# NANO100BN_v1 register map
File version: 1.0
Registers are 32-bit, read-write, reset 0x0 unless marked. A register's access mark holds for its fields unless they carry their own. Offsets are from the block's base; [hi:lo] are bit positions; {n}, {i} and the like mark numbered series; 'fields as' and 'values as' point back to an identical list.

## ADC — ADC Register Map
Base 0x400E0000
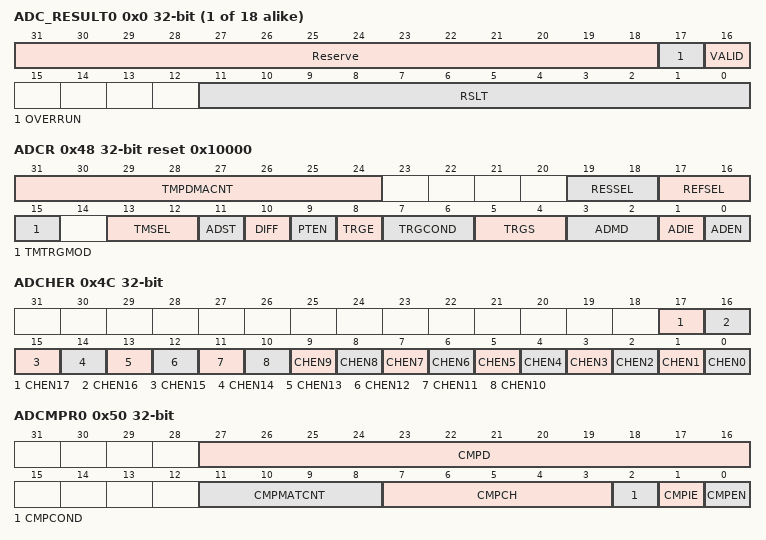
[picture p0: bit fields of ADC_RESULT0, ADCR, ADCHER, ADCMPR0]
{0x0+4i} ADC_RESULT{i} ro (i=0..17) — A/D Data Register {i}
  [31:18] Reserve — Reserved
  [17] OVERRUN — Over Run Flag. It is a mirror to OVERRUN bit in ADC_RESULTx
  [16] VALID — Data Valid Flag. It is a mirror of VALID bit in ADC_RESULTx
  [11:0] RSLT — A/D Conversion Result. This field contains 12 bits conversion results.
0x48 ADCR reset 0x10000 — A/D Control Register
  [31:24] TMPDMACNT — PDMA Count. When each timer event occur PDMA will transfer TMPDMACNT +1 ADC result in the amount of this register setting. Note: The total amount of PDMA transferring data should be set in PDMA byte count register. When PDMA finish is set, ADC will not be enabled and start transfer even though the timer event occurred
  [19:18] RESSEL — Resolution Selection
  [17:16] REFSEL — Reference Voltage Source Selection
  [15] TMTRGMOD — Timer Event Trigger ADC Conversion
    0=This function Disabled; 1=ADC Enabled by TIMER OUT event
  [13:12] TMSEL — Select A/D Enable Time-out Source
  [11] ADST — A/D Conversion Start. ADST bit can be set to 1 from two sources: software write and external pin STADC. ADST is cleared to 0 by hardware automatically at the end of single mode and single-cycle scan mode on specified channels. In continuous scan mode, A/D conversion is continuously performed sequentially unless software writes 0 to this bit or chip reset. Note: After ADC conversion done, SW needs to wait at least one ADC clock before to set this bit high again.
    0=Conversion stopped and A/D converter enter idle state; 1=Conversion starts
  [10] DIFF — Differential Mode Selection. 1:ADC is operated in differential mode. 0:ADC is operated in single-ended mode. Note: Calibration should calibrated each time when switching between single-ended and differential mode
  [9] PTEN — PDMA Transfer Enable
    0=PDMA data transfer Disabled; 1=PDMA data transfer in ADC_RESULT 0~17 Enabled
  [8] TRGE — External Trigger Enable. Enable or disable triggering of A/D conversion by external STADC pin.
    0=Disabled,; 1=Enabled,
  [7:6] TRGCOND — External Trigger Condition
  [5:4] TRGS — Hardware Trigger Source
  [3:2] ADMD — A/D Converter Operation Mode
  [1] ADIE — A/D Interrupt Enable. A/D conversion end interrupt request is generated if ADIE bit is set to 1.
    0=A/D interrupt function Disabled; 1=A/D interrupt function Enabled
  [0] ADEN — A/D Converter Enable. Before starting A/D conversion, this bit should be set to 1. Clear it to 0 to disable A/D converter analog circuit power consumption.
    0=Disabled; 1=Enabled
0x4C ADCHER — A/D Channel Enable Register
  [all] fields
    0=Disabled; 1=Enabled
  [17] CHEN17 — Analog Input Channel 17 Enable (Convert AVSS)
  [16] CHEN16 — Analog Input Channel 16 Enable (Convert AVDD)
  [15] CHEN15 — Analog Input Channel 15 Enable (Convert Int_VREF)
  [14] CHEN14 — Analog Input Channel 14 Enable (Convert VTEMP)
  [13] CHEN13 — Analog Input Channel 13 Enable (Convert DAC1 Output Voltage)
  [12] CHEN12 — Analog Input Channel 12 Enable (Convert DAC0 Output Voltage)
  [11] CHEN11 — Analog Input Channel 11 Enable(Convert input voltage from PD.3 )
  [10] CHEN10 — Analog Input Channel 10 Enable (Convert Input Voltage from PD.2 )
  [9] CHEN9 — Analog Input Channel 9 Enable for DAC1 (Convert Input Voltage from PD.1 )
  [8] CHEN8 — Analog Input Channel 8 Enable for DAC0 (Convert Input Voltage from PD.0 )
  [7] CHEN7 — Analog Input Channel 7 Enable (Convert Input Voltage from PA.7 )
  [6] CHEN6 — Anaslog Input Channel 6 Enable (Convert Input Voltage from PA.6 )
  [5] CHEN5 — Analog Input Channel 5 Enable (Convert Input Voltage from PA.5 )
  [4] CHEN4 — Analog Input Channel 4 Enable (Convert Input Voltage from PA.4 )
  [3] CHEN3 — Analog Input Channel 3 Enable(Convert input voltage from PA.3 )
  [2] CHEN2 — Analog Input Channel 2 Enable (Convert Input Voltage from PA.2 )
  [1] CHEN1 — Analog Input Channel 1 Enable(Convert input voltage from PA.1 )
  [0] CHEN0 — Analog Input Channel 0 Enable (Convert Input Voltage from PA.0 ). If more than one channel in single mode is enabled by software, the least channel is converted and other enabled channels will be ignored.
0x50 ADCMPR0 — A/D Compare Register 0
  [27:16] CMPD — Comparison Data. The 12 bits data is used to compare with conversion result of specified channel. Software can use it to monitor the external analog input pin voltage variation in scan mode without imposing a load on software.
  [11:8] CMPMATCNT — Compare Match Count. When the specified A/D channel analog conversion result matches the compare condition defined by CMPCOND[2], the internal match counter will increase 1. When the internal counter reaches the value to (CMPMATCNT +1), the CMPF bit will be set.
  [7:3] CMPCH — Compare Channel Selection
  [2] CMPCOND — Compare Condition. Note: When the internal counter reaches the value to (CMPMATCNT +1), the CMPF bit will be set.
    0=Set the compare condition as that when a 12-bit A/D conversion result is less than the 12-bit CMPD (ADCMPRx[27:16]), the internal match counter will increase one; 1=Set the compare condition as that when a 12-bit A/D conversion result is greater or equal to the 12-bit CMPD (ADCMPRx[27:16]), the internal match counter will increase by one
  [1] CMPIE — Compare Interrupt Enable. If the compare function is enabled and the compare condition matches the setting of CMPCOND and CMPMATCNT, CMPF bit will be asserted, in the meanwhile, if CMPIE is set to 1, a compare interrupt request is generated.
    0=Compare function interrupt Disabled; 1=Compare function interrupt Enabled
  [0] CMPEN — Compare Enable. Set this bit to 1 to enable compare CMPD[11:0] with specified channel conversion result when converted data is loaded into ADC_RESULTx register. When this bit is set to 1, and CMPMATCNT is 0, the CMPF will be set once the match is hit
    0=Compare Disabled; 1=Compare Enabled
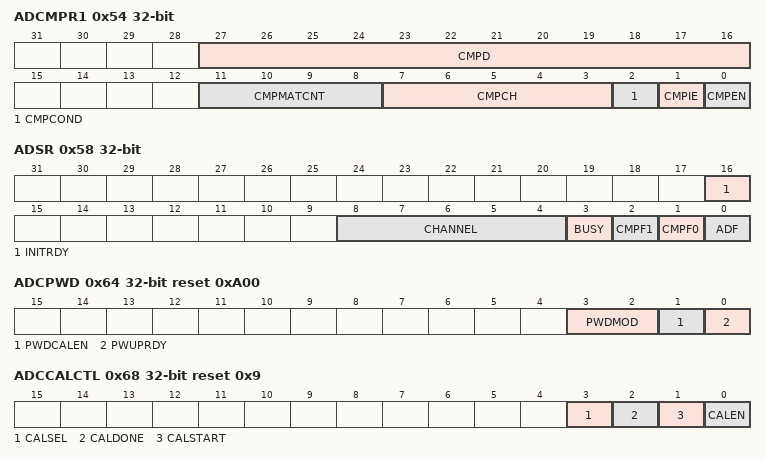
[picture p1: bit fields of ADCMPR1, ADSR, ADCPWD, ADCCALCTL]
0x54 ADCMPR1 — A/D Compare Register 1
  fields as ADCMPR0
0x58 ADSR — A/D Status Register
  [16] INITRDY — ADC Power-up Sequence Completed. Note: This bit will be set after system reset occurred and automatically cleared by power-up event.
    0=ADC has been powered up since he last system reset; 1=ADC not powered up after system reset
  [8:4] CHANNEL — Current Conversion Channel. It is read only.
  [3] BUSY — BUSY/IDLE. It is read only.
    0=A/D converter is in idle state; 1=A/D converter is busy at conversion
  [2] CMPF1 — Compare Flag. When the selected channel A/D conversion result meets setting condition in ADCMPR1 then this bit is set to 1. And it is cleared by writing 1 to self. This flag can be cleared by writing 1 to it. Note: when this flag is set, the matching counter will be reset to 0,and continue to count when user write 1 to clear CMPF1
    0=Conversion result in ADC_RESULTx does not meet ADCMPR1 setting; 1=Conversion result in ADC_RESULTx meets ADCMPR1 setting
  [1] CMPF0 — Compare Flag. When the selected channel A/D conversion result meets setting condition in ADCMPR0 then this bit is set to 1. And it is cleared by writing 1 to self. This flag can be cleared by writing 1 to it. Note: When this flag is set, the matching counter will be reset to 0,and continue to count when user write 1 to clear CMPF0
    0=Conversion result in ADC_RESULTx does not meet ADCMPR0setting; 1=Conversion result in ADC_RESULTx meets ADCMPR0setting
  [0] ADF — A/D Conversion End Flag. A status flag that indicates the end of A/D conversion. ADF is set to 1 at these two conditions: When A/D conversion ends in single mode. When A/D conversion ends on all specified channels in scan mode. This flag can be cleared by writing 1 to it.
0x60 ADPDMA ro — A/D PDMA current transfer data Register
  [11:0] AD_PDMA — ADC PDMA Current Transfer Data Register. When PDMA transferring, read this register can monitor current PDMA transfer data. This is a read only register.
0x64 ADCPWD reset 0xA00 — ADC Power Management Register
  [3:2] PWDMOD — Power-down Mode
  [1] PWDCALEN — Power up Calibration Function Enable
    0=Power up without calibration; 1=Power up with calibration
  [0] PWUPRDY — ADC Power-up Sequence Completed and Ready for Conversion
    0=ADC is not ready for conversion;may be in power down state or in the progress of power up; 1=ADC is ready for conversion
0x68 ADCCALCTL reset 0x9 — ADC Calibration Control Register
  [3] CALSEL — Select Calibration Functional Block
    0=Load calibration functional block; 1=Calibration functional block
  [2] CALDONE — Calibrate Functional Block Complete
    0=Not yet; 1=Selected functional block complete
  [1] CALSTART — Calibration Functional Blcok Start
    0=Stops calibration functional block; 1=Starts calibration functional block
  [0] CALEN — Calibraion Function Enable. Enable this bit to turn on the calibration function block.
    0=(BYPASSCAL); 1=Enabled
0x6C ADCCALWORD reset not defined — A/D calibration load word register
  [6:0] CALWORD — Calibration Word Register. Write to this register with the previous calibration word before load calibration action. Read this register after calibration done. Note: The calibration block contains two parts "CALIBRATION" and "LOAD CALIBRATION"; if thecalibration block is config as "CALIBRATION"; then this register represent the result of calibration when calibration is completed; if config as "LOAD CALIBRATION" ; config this register before loading calibration action, after loading calibration complete, the laoded calibration word will apply to the ADC;while in loading calibration function the loaded value will not be equal to the orginal CALWORD until calibration is done.
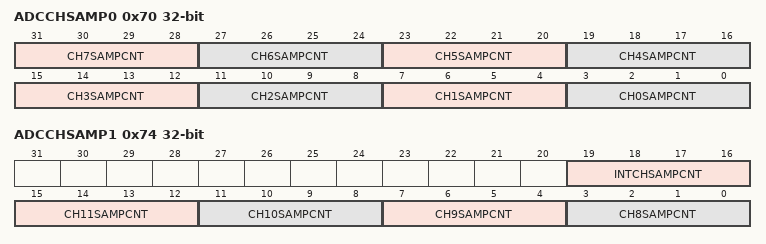
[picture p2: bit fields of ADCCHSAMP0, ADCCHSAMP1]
0x70 ADCCHSAMP0 — ADC Channel Sampling Time Counter Register Group 0
  [4n+3:4n] CH{n}SAMPCNT (n=1..7) — Channel {n} Sampling Counter. The same as Channel 0 sampling counter table.
  [3:0] CH0SAMPCNT — Channel 0 Sampling Counter
0x74 ADCCHSAMP1 — ADC Channel Sampling Time Counter Register Group 1
  [19:16] INTCHSAMPCNT — Internal Channel (VTEMP, AVDD, AVSS, Int_VREF, DAC0, DAC1) Sampling Counter. The same as Channel 0 sampling counter table.
  [4n-29:4n-32] CH{n}SAMPCNT (n=8..11) — Channel {n} Sampling Counter. The same as Channel 0 sampling counter table.
